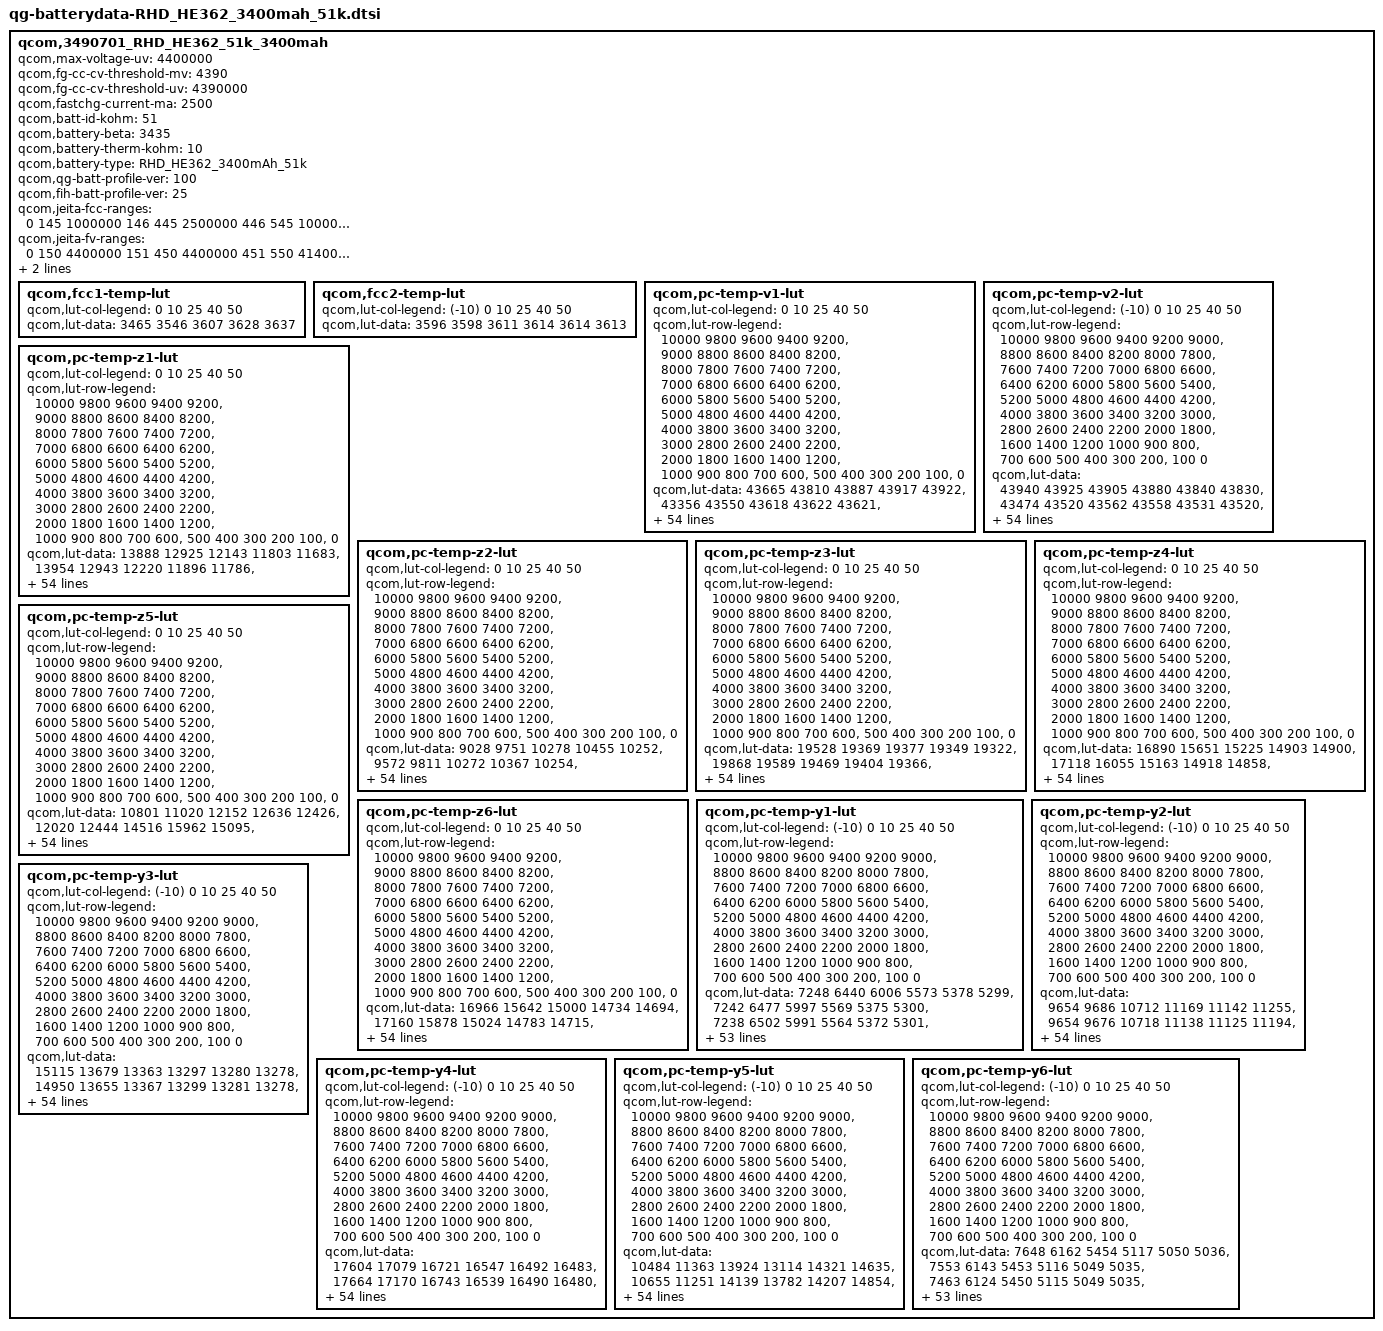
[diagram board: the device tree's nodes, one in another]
qcom,3490701_RHD_HE362_51k_3400mah {
	/* 3490701_FIH_HE362_3500mAh_averaged_MasterSlave_Jul26th2018 */
	qcom,max-voltage-uv = <4400000>;
	qcom,fg-cc-cv-threshold-mv = <4390>;
	qcom,fg-cc-cv-threshold-uv = <4390000>; // not use
	qcom,fastchg-current-ma = <2500>;
	qcom,batt-id-kohm = <51>;
	qcom,battery-beta = <3435>;
	qcom,battery-therm-kohm = <10>;
	qcom,battery-type =
		"RHD_HE362_3400mAh_51k";
	qcom,qg-batt-profile-ver = <100>;
	qcom,fih-batt-profile-ver = <25>;

	qcom,jeita-fcc-ranges = <0   145   1000000
				 146 445  2500000
				 446 545  1000000
				 546 550  100000>;
	qcom,jeita-fv-ranges =  <0   150  4400000
				 151 450  4400000
				 451 550  4140000>;

	qcom,jeita-soft-thresholds = <0x257d 0xfb3>; 
	qcom,jeita-hard-thresholds = <0x3733 0xbc2>;

	qcom,fcc1-temp-lut {
		qcom,lut-col-legend = <0 10 25 40 50>;
		qcom,lut-data = <3465 3546 3607 3628 3637>;
	};

	qcom,fcc2-temp-lut {
		qcom,lut-col-legend = <(-10) 0 10 25 40 50>;
		qcom,lut-data = <3596 3598 3611 3614 3614 3613>;
	};

	qcom,pc-temp-v1-lut {
		qcom,lut-col-legend = <0 10 25 40 50>;
		qcom,lut-row-legend = <10000 9800 9600 9400 9200>,
			<9000 8800 8600 8400 8200>,
			<8000 7800 7600 7400 7200>,
			<7000 6800 6600 6400 6200>,
			<6000 5800 5600 5400 5200>,
			<5000 4800 4600 4400 4200>,
			<4000 3800 3600 3400 3200>,
			<3000 2800 2600 2400 2200>,
			<2000 1800 1600 1400 1200>,
			<1000 900 800 700 600>,
			<500 400 300 200 100>,
			<0>;
		qcom,lut-data = <43665 43810 43887 43917 43922>,
			<43356 43550 43618 43622 43621>,
			<43072 43273 43356 43371 43365>,
			<42816 43000 43101 43124 43119>,
			<42577 42745 42851 42876 42877>,
			<42342 42500 42603 42631 42635>,
			<42113 42262 42358 42389 42395>,
			<41890 42030 42118 42149 42157>,
			<41671 41804 41880 41911 41923>,
			<41457 41583 41649 41676 41691>,
			<41257 41368 41419 41447 41461>,
			<41079 41171 41202 41223 41233>,
			<40888 40999 41009 41004 41012>,
			<40629 40807 40830 40791 40798>,
			<40330 40535 40621 40585 40590>,
			<40101 40242 40358 40384 40390>,
			<39935 40044 40122 40191 40198>,
			<39792 39906 39961 40012 40015>,
			<39654 39776 39825 39842 39840>,
			<39526 39645 39681 39679 39673>,
			<39403 39514 39537 39530 39523>,
			<39284 39369 39364 39365 39361>,
			<39168 39214 39096 39134 39143>,
			<39056 39042 38824 38879 38897>,
			<38949 38817 38681 38711 38718>,
			<38844 38607 38589 38597 38589>,
			<38741 38502 38506 38496 38478>,
			<38643 38435 38425 38393 38377>,
			<38550 38383 38350 38298 38287>,
			<38461 38343 38278 38217 38203>,
			<38393 38307 38212 38146 38128>,
			<38340 38269 38155 38083 38060>,
			<38297 38231 38107 38030 38003>,
			<38260 38195 38065 37981 37950>,
			<38230 38165 38028 37941 37904>,
			<38205 38133 37994 37904 37862>,
			<38189 38100 37958 37862 37814>,
			<38173 38065 37922 37818 37760>,
			<38139 38015 37875 37763 37695>,
			<38070 37931 37797 37687 37615>,
			<37982 37828 37696 37591 37520>,
			<37863 37715 37586 37483 37412>,
			<37720 37583 37459 37357 37286>,
			<37558 37419 37306 37205 37135>,
			<37392 37262 37155 37057 36991>,
			<37264 37172 37054 36960 36901>,
			<37223 37148 37026 36936 36875>,
			<37190 37121 37008 36919 36857>,
			<37155 37096 36991 36900 36839>,
			<37106 37055 36954 36855 36784>,
			<36934 36856 36755 36620 36520>,
			<36474 36402 36320 36171 36058>,
			<35825 35759 35692 35542 35435>,
			<34864 34757 34770 34653 34545>,
			<33230 33191 33337 33243 33145>,
			<30000 30000 30000 30000 30000>;
	};

	qcom,pc-temp-v2-lut {
		qcom,lut-col-legend = <(-10) 0 10 25 40 50>;
		qcom,lut-row-legend = <10000 9800 9600 9400 9200 9000>,
			<8800 8600 8400 8200 8000 7800>,
			<7600 7400 7200 7000 6800 6600>,
			<6400 6200 6000 5800 5600 5400>,
			<5200 5000 4800 4600 4400 4200>,
			<4000 3800 3600 3400 3200 3000>,
			<2800 2600 2400 2200 2000 1800>,
			<1600 1400 1200 1000 900 800>,
			<700 600 500 400 300 200>,
			<100 0>;
		qcom,lut-data = <43940 43925 43905 43880 43840 43830>,
			<43474 43520 43562 43558 43531 43520>,
			<43059 43153 43247 43259 43241 43230>,
			<42701 42828 42960 42986 42973 42962>,
			<42389 42539 42700 42736 42725 42715>,
			<42103 42273 42449 42492 42481 42473>,
			<41832 42030 42199 42248 42238 42231>,
			<41586 41798 41957 42009 42000 41993>,
			<41377 41548 41722 41774 41765 41758>,
			<41191 41291 41494 41543 41533 41526>,
			<41027 41088 41273 41316 41307 41298>,
			<40898 40951 41064 41094 41085 41075>,
			<40740 40802 40854 40877 40868 40857>,
			<40393 40534 40637 40671 40658 40648>,
			<39897 40183 40415 40470 40452 40444>,
			<39584 39924 40193 40263 40254 40248>,
			<39402 39742 39967 40047 40062 40057>,
			<39234 39561 39762 39853 39880 39875>,
			<39043 39347 39592 39698 39712 39706>,
			<38855 39124 39429 39550 39547 39541>,
			<38686 38921 39232 39362 39371 39366>,
			<38529 38729 39003 39138 39185 39185>,
			<38398 38560 38803 38928 38990 38992>,
			<38292 38409 38640 38731 38768 38770>,
			<38202 38280 38496 38558 38566 38566>,
			<38121 38179 38362 38427 38430 38429>,
			<38050 38097 38238 38320 38324 38323>,
			<37983 38029 38137 38222 38227 38224>,
			<37920 37970 38052 38132 38138 38132>,
			<37860 37919 37981 38051 38057 38048>,
			<37806 37873 37920 37977 37984 37975>,
			<37756 37833 37869 37909 37917 37907>,
			<37708 37797 37832 37851 37858 37848>,
			<37662 37764 37806 37801 37806 37796>,
			<37615 37734 37779 37755 37750 37736>,
			<37567 37703 37747 37715 37682 37650>,
			<37517 37672 37711 37674 37609 37554>,
			<37462 37634 37667 37621 37532 37466>,
			<37404 37587 37612 37552 37451 37382>,
			<37327 37526 37545 37479 37374 37303>,
			<37199 37437 37459 37401 37305 37232>,
			<37029 37324 37351 37305 37219 37146>,
			<36804 37180 37217 37183 37099 37027>,
			<36635 36995 37056 37054 36972 36902>,
			<36547 36753 36862 36898 36821 36762>,
			<36429 36619 36758 36838 36785 36729>,
			<36366 36572 36717 36818 36769 36714>,
			<36300 36513 36674 36793 36747 36695>,
			<36224 36436 36623 36754 36713 36660>,
			<36112 36321 36528 36671 36626 36557>,
			<35886 36087 36289 36421 36338 36226>,
			<35442 35550 35776 35919 35823 35699>,
			<34781 34748 35048 35228 35129 34986>,
			<33819 33748 33939 34269 34156 33982>,
			<32276 32311 32325 32813 32666 32410>,
			<28288 28796 27593 28640 28095 27772>;
	};

	qcom,pc-temp-z1-lut {
		qcom,lut-col-legend = <0 10 25 40 50>;
		qcom,lut-row-legend = <10000 9800 9600 9400 9200>,
			<9000 8800 8600 8400 8200>,
			<8000 7800 7600 7400 7200>,
			<7000 6800 6600 6400 6200>,
			<6000 5800 5600 5400 5200>,
			<5000 4800 4600 4400 4200>,
			<4000 3800 3600 3400 3200>,
			<3000 2800 2600 2400 2200>,
			<2000 1800 1600 1400 1200>,
			<1000 900 800 700 600>,
			<500 400 300 200 100>,
			<0>;
		qcom,lut-data = <13888 12925 12143 11803 11683>,
			<13954 12943 12220 11896 11786>,
			<13996 12967 12228 11897 11787>,
			<14013 12982 12223 11892 11784>,
			<14025 12987 12219 11888 11782>,
			<14034 12990 12215 11884 11780>,
			<14043 12992 12213 11879 11778>,
			<14049 12993 12210 11876 11775>,
			<14060 12997 12203 11874 11773>,
			<14078 13006 12199 11872 11771>,
			<14082 13018 12199 11870 11770>,
			<14070 13019 12199 11869 11770>,
			<14054 13011 12198 11869 11771>,
			<14037 13001 12196 11869 11771>,
			<14015 12988 12194 11869 11772>,
			<14009 12974 12188 11870 11774>,
			<14031 12973 12184 11872 11776>,
			<14051 12982 12185 11872 11778>,
			<14043 12987 12189 11873 11780>,
			<14022 12990 12193 11874 11781>,
			<14013 12994 12200 11877 11783>,
			<14008 12997 12204 11881 11785>,
			<14002 13006 12205 11883 11788>,
			<14012 13015 12206 11886 11792>,
			<14044 13022 12209 11889 11795>,
			<14069 13029 12216 11894 11799>,
			<14085 13034 12221 11898 11803>,
			<14098 13042 12224 11903 11807>,
			<14110 13046 12227 11907 11810>,
			<14123 13060 12232 11910 11814>,
			<14127 13074 12238 11914 11817>,
			<14115 13066 12242 11917 11820>,
			<14102 13045 12243 11919 11823>,
			<14104 13037 12244 11922 11825>,
			<14118 13042 12249 11925 11828>,
			<14130 13050 12253 11930 11831>,
			<14136 13062 12254 11932 11834>,
			<14139 13080 12252 11933 11836>,
			<14136 13090 12251 11934 11839>,
			<14128 13096 12258 11938 11841>,
			<14124 13099 12265 11944 11843>,
			<14144 13095 12268 11948 11846>,
			<14160 13091 12269 11952 11849>,
			<14130 13101 12269 11952 11851>,
			<14080 13109 12270 11952 11853>,
			<14077 13082 12283 11957 11855>,
			<14092 13090 12275 11957 11855>,
			<14140 13078 12274 11957 11857>,
			<14045 13079 12274 11958 11859>,
			<14052 13095 12279 11966 11864>,
			<14061 13110 12292 11972 11871>,
			<14074 13138 12305 11983 11879>,
			<14089 13146 12319 12000 11894>,
			<14144 13173 12345 12024 11916>,
			<14144 13173 12345 12024 11916>,
			<14144 13173 12345 12024 11916>;
	};

	qcom,pc-temp-z2-lut {
		qcom,lut-col-legend = <0 10 25 40 50>;
		qcom,lut-row-legend = <10000 9800 9600 9400 9200>,
			<9000 8800 8600 8400 8200>,
			<8000 7800 7600 7400 7200>,
			<7000 6800 6600 6400 6200>,
			<6000 5800 5600 5400 5200>,
			<5000 4800 4600 4400 4200>,
			<4000 3800 3600 3400 3200>,
			<3000 2800 2600 2400 2200>,
			<2000 1800 1600 1400 1200>,
			<1000 900 800 700 600>,
			<500 400 300 200 100>,
			<0>;
		qcom,lut-data = <9028 9751 10278 10455 10252>,
			<9572 9811 10272 10367 10254>,
			<9873 9926 10272 10391 10397>,
			<9933 10024 10247 10375 10397>,
			<9966 10012 10216 10351 10391>,
			<9973 9976 10187 10329 10384>,
			<9969 9948 10163 10308 10363>,
			<9963 9925 10166 10305 10334>,
			<9955 9912 10184 10333 10284>,
			<9944 9909 10198 10354 10248>,
			<9931 9908 10208 10351 10254>,
			<9917 9913 10219 10346 10269>,
			<9899 9948 10235 10343 10273>,
			<9859 9972 10253 10348 10262>,
			<9804 9971 10257 10347 10260>,
			<9791 9968 10250 10324 10277>,
			<9822 9973 10246 10298 10295>,
			<9853 10005 10256 10294 10302>,
			<9853 10037 10277 10294 10306>,
			<9844 10061 10293 10300 10311>,
			<9837 10080 10309 10329 10321>,
			<9828 10090 10315 10359 10336>,
			<9821 10098 10298 10362 10354>,
			<9822 10102 10271 10346 10379>,
			<9829 10089 10255 10348 10424>,
			<9837 10073 10243 10409 10522>,
			<9850 10076 10242 10447 10576>,
			<9866 10093 10281 10412 10468>,
			<9880 10105 10319 10357 10314>,
			<9895 10111 10305 10325 10278>,
			<9909 10116 10272 10295 10265>,
			<9923 10120 10263 10287 10262>,
			<9936 10123 10266 10302 10268>,
			<9952 10128 10270 10326 10274>,
			<9971 10139 10289 10357 10279>,
			<9974 10152 10319 10396 10290>,
			<9785 10164 10340 10426 10307>,
			<9531 10178 10355 10449 10351>,
			<9446 10193 10372 10470 10390>,
			<9395 10213 10398 10495 10417>,
			<9375 10229 10420 10516 10442>,
			<9376 10233 10423 10517 10437>,
			<9379 10236 10420 10510 10413>,
			<9407 10253 10430 10480 10399>,
			<9439 10346 10462 10461 10394>,
			<9437 10293 10529 10503 10417>,
			<9421 10048 10510 10470 10414>,
			<9451 9984 10513 10481 10397>,
			<9447 10104 10540 10477 10469>,
			<9428 10119 10548 10573 10607>,
			<9400 9990 10685 10470 10307>,
			<9321 9877 10657 10324 10172>,
			<9256 9640 10375 10252 10116>,
			<9166 10084 10236 10123 10043>,
			<9166 10084 10236 10123 10043>,
			<9166 10084 10236 10123 10043>;
	};

	qcom,pc-temp-z3-lut {
		qcom,lut-col-legend = <0 10 25 40 50>;
		qcom,lut-row-legend = <10000 9800 9600 9400 9200>,
			<9000 8800 8600 8400 8200>,
			<8000 7800 7600 7400 7200>,
			<7000 6800 6600 6400 6200>,
			<6000 5800 5600 5400 5200>,
			<5000 4800 4600 4400 4200>,
			<4000 3800 3600 3400 3200>,
			<3000 2800 2600 2400 2200>,
			<2000 1800 1600 1400 1200>,
			<1000 900 800 700 600>,
			<500 400 300 200 100>,
			<0>;
		qcom,lut-data = <19528 19369 19377 19349 19322>,
			<19868 19589 19469 19404 19366>,
			<20033 19713 19531 19431 19403>,
			<20017 19785 19544 19443 19418>,
			<19977 19806 19549 19449 19423>,
			<19939 19818 19550 19450 19423>,
			<19894 19820 19550 19449 19418>,
			<19866 19814 19548 19447 19412>,
			<19869 19806 19539 19440 19400>,
			<19878 19798 19530 19433 19390>,
			<19884 19787 19522 19424 19387>,
			<19885 19767 19512 19416 19386>,
			<19889 19722 19500 19411 19384>,
			<19937 19694 19487 19409 19379>,
			<20032 19710 19484 19405 19375>,
			<20066 19736 19493 19399 19370>,
			<20051 19734 19500 19391 19366>,
			<20031 19697 19493 19386 19364>,
			<20005 19670 19481 19382 19362>,
			<19954 19661 19474 19381 19360>,
			<19937 19655 19469 19381 19357>,
			<19958 19659 19467 19382 19355>,
			<19981 19678 19482 19385 19355>,
			<19987 19692 19500 19389 19357>,
			<19991 19700 19495 19388 19366>,
			<19992 19705 19472 19382 19406>,
			<19988 19705 19464 19379 19431>,
			<19983 19703 19477 19410 19426>,
			<19977 19700 19495 19447 19418>,
			<19970 19694 19508 19448 19412>,
			<19961 19687 19520 19443 19406>,
			<19946 19682 19522 19436 19400>,
			<19925 19679 19513 19429 19394>,
			<19907 19675 19503 19421 19388>,
			<19887 19668 19497 19414 19380>,
			<19851 19660 19491 19406 19372>,
			<19660 19654 19485 19401 19368>,
			<19429 19649 19481 19396 19365>,
			<19347 19643 19476 19393 19364>,
			<19297 19638 19472 19391 19365>,
			<19277 19633 19467 19388 19367>,
			<19277 19625 19464 19385 19365>,
			<19277 19616 19461 19380 19361>,
			<19275 19607 19454 19375 19360>,
			<19272 19576 19443 19372 19359>,
			<19272 19401 19427 19371 19347>,
			<19273 19273 19427 19360 19342>,
			<19271 19265 19418 19352 19340>,
			<19271 19264 19397 19352 19330>,
			<19272 19264 19396 19342 19319>,
			<19273 19265 19359 19356 19359>,
			<19278 19266 19348 19372 19375>,
			<19284 19274 19432 19401 19372>,
			<19312 19611 19477 19402 19390>,
			<19312 19611 19477 19402 19390>,
			<19312 19611 19477 19402 19390>;
	};

	qcom,pc-temp-z4-lut {
		qcom,lut-col-legend = <0 10 25 40 50>;
		qcom,lut-row-legend = <10000 9800 9600 9400 9200>,
			<9000 8800 8600 8400 8200>,
			<8000 7800 7600 7400 7200>,
			<7000 6800 6600 6400 6200>,
			<6000 5800 5600 5400 5200>,
			<5000 4800 4600 4400 4200>,
			<4000 3800 3600 3400 3200>,
			<3000 2800 2600 2400 2200>,
			<2000 1800 1600 1400 1200>,
			<1000 900 800 700 600>,
			<500 400 300 200 100>,
			<0>;
		qcom,lut-data = <16890 15651 15225 14903 14900>,
			<17118 16055 15163 14918 14858>,
			<17180 15881 15267 15001 14919>,
			<16994 15651 15145 14960 14895>,
			<16608 15471 15030 14901 14852>,
			<16343 15303 14966 14860 14820>,
			<16161 15184 14915 14827 14793>,
			<16005 15098 14871 14806 14783>,
			<15864 15032 14833 14792 14781>,
			<15739 14981 14812 14782 14779>,
			<15626 14940 14805 14774 14772>,
			<15522 14908 14798 14768 14761>,
			<15431 14878 14783 14760 14752>,
			<15356 14860 14764 14749 14745>,
			<15288 14855 14759 14740 14738>,
			<15226 14851 14761 14736 14731>,
			<15158 14843 14763 14733 14724>,
			<15110 14830 14749 14727 14716>,
			<15096 14816 14724 14719 14707>,
			<15083 14801 14719 14712 14702>,
			<15056 14788 14719 14706 14700>,
			<14996 14784 14722 14704 14698>,
			<14937 14784 14812 14765 14747>,
			<14905 14789 14927 14874 14847>,
			<14882 14880 14941 14895 14864>,
			<14873 14988 14938 14886 14811>,
			<14870 14994 14929 14871 14766>,
			<14869 14971 14891 14821 14751>,
			<14872 14945 14844 14762 14741>,
			<14880 14913 14811 14744 14732>,
			<14883 14881 14783 14735 14723>,
			<14879 14857 14769 14729 14717>,
			<14871 14836 14762 14723 14710>,
			<14864 14818 14757 14719 14707>,
			<14856 14804 14753 14719 14707>,
			<14856 14792 14749 14719 14709>,
			<15038 14782 14748 14720 14712>,
			<15275 14774 14747 14723 14719>,
			<15337 14773 14747 14728 14723>,
			<15357 14777 14753 14732 14722>,
			<15358 14781 14761 14736 14720>,
			<15346 14775 14756 14734 14716>,
			<15327 14764 14743 14725 14709>,
			<15296 14758 14741 14729 14712>,
			<15187 14743 14733 14730 14714>,
			<15124 14853 14703 14699 14697>,
			<15119 14985 14692 14697 14689>,
			<15111 14986 14685 14685 14669>,
			<15104 14976 14690 14662 14657>,
			<15100 14971 14688 14672 14667>,
			<15101 14986 14753 14689 14661>,
			<15147 15012 14780 14685 14663>,
			<15194 15034 14703 14678 14683>,
			<15290 14768 14730 14719 14698>,
			<15290 14768 14730 14719 14698>,
			<15290 14768 14730 14719 14698>;
	};

	qcom,pc-temp-z5-lut {
		qcom,lut-col-legend = <0 10 25 40 50>;
		qcom,lut-row-legend = <10000 9800 9600 9400 9200>,
			<9000 8800 8600 8400 8200>,
			<8000 7800 7600 7400 7200>,
			<7000 6800 6600 6400 6200>,
			<6000 5800 5600 5400 5200>,
			<5000 4800 4600 4400 4200>,
			<4000 3800 3600 3400 3200>,
			<3000 2800 2600 2400 2200>,
			<2000 1800 1600 1400 1200>,
			<1000 900 800 700 600>,
			<500 400 300 200 100>,
			<0>;
		qcom,lut-data = <10801 11020 12152 12636 12426>,
			<12020 12444 14516 15962 15095>,
			<12675 13477 15198 15871 16573>,
			<12755 14333 15608 16200 17288>,
			<12797 14998 16012 16700 17700>,
			<12831 15546 16427 17157 18074>,
			<12862 16006 16882 17592 18389>,
			<12906 16386 17566 17877 18404>,
			<13031 16751 18490 18174 17617>,
			<13211 17232 18839 18351 16947>,
			<13277 17686 18768 18188 17110>,
			<13241 17682 18672 17909 17513>,
			<13218 17106 18584 17977 17775>,
			<13698 16715 18498 18553 17914>,
			<14799 18602 18623 18870 17929>,
			<15506 21585 19913 18639 17969>,
			<15824 21780 21301 18343 18143>,
			<15939 20006 22102 18476 18639>,
			<15636 18929 22758 19037 19616>,
			<14953 19394 23083 19756 20279>,
			<14869 20457 23302 20951 20734>,
			<16048 22991 23745 21731 21000>,
			<17812 29532 27933 21529 20115>,
			<19593 33932 32941 20890 18194>,
			<21704 35716 30748 19551 17802>,
			<23946 36778 22145 16363 18682>,
			<26499 36036 18641 14803 19575>,
			<28941 32976 18913 17221 19997>,
			<31000 30482 19485 20934 20403>,
			<32947 28698 21503 23010 21127>,
			<33588 27554 25340 24502 22289>,
			<32513 27679 27409 25887 23471>,
			<30727 28305 28397 27519 24853>,
			<29064 28814 29151 28523 25758>,
			<27050 29361 29999 28516 25698>,
			<24258 29905 30729 28376 25401>,
			<18080 30509 30718 27952 24924>,
			<12096 31359 29993 26325 23850>,
			<11125 31723 28998 24552 22781>,
			<10942 31837 27336 22901 22091>,
			<10889 31872 25633 21280 21445>,
			<10911 30632 24954 20214 20535>,
			<10941 28745 24529 19407 19419>,
			<10966 28593 22900 18138 18699>,
			<11139 27423 22355 17692 17995>,
			<11232 17507 22845 19055 16978>,
			<11218 11650 22927 17455 16640>,
			<11170 11285 21557 17178 17495>,
			<11157 11230 18148 18852 17309>,
			<11156 11231 18310 16890 15458>,
			<11181 11292 14268 16165 19645>,
			<11156 11211 13142 17231 22018>,
			<11052 11165 20058 22840 18779>,
			<11085 27605 25375 18676 18980>,
			<11085 27605 25375 18676 18980>,
			<11085 27605 25375 18676 18980>;
	};

	qcom,pc-temp-z6-lut {
		qcom,lut-col-legend = <0 10 25 40 50>;
		qcom,lut-row-legend = <10000 9800 9600 9400 9200>,
			<9000 8800 8600 8400 8200>,
			<8000 7800 7600 7400 7200>,
			<7000 6800 6600 6400 6200>,
			<6000 5800 5600 5400 5200>,
			<5000 4800 4600 4400 4200>,
			<4000 3800 3600 3400 3200>,
			<3000 2800 2600 2400 2200>,
			<2000 1800 1600 1400 1200>,
			<1000 900 800 700 600>,
			<500 400 300 200 100>,
			<0>;
		qcom,lut-data = <16966 15642 15000 14734 14694>,
			<17160 15878 15024 14783 14715>,
			<17221 15826 15092 14833 14761>,
			<17095 15749 15041 14818 14755>,
			<16833 15666 14991 14797 14743>,
			<16646 15571 14961 14781 14730>,
			<16510 15500 14935 14765 14717>,
			<16401 15445 14910 14752 14706>,
			<16319 15400 14887 14742 14699>,
			<16251 15364 14872 14734 14693>,
			<16189 15334 14863 14725 14687>,
			<16121 15299 14855 14718 14682>,
			<16079 15255 14841 14711 14676>,
			<16071 15232 14825 14705 14671>,
			<16068 15235 14820 14699 14665>,
			<16059 15239 14824 14694 14660>,
			<16024 15236 14827 14688 14655>,
			<15980 15212 14818 14683 14650>,
			<15943 15193 14802 14678 14646>,
			<15908 15183 14798 14675 14642>,
			<15888 15177 14797 14673 14640>,
			<15875 15178 14797 14672 14639>,
			<15868 15189 14844 14700 14661>,
			<15865 15206 14904 14750 14706>,
			<15863 15254 14909 14760 14717>,
			<15863 15302 14900 14754 14716>,
			<15863 15305 14890 14748 14713>,
			<15863 15296 14882 14743 14707>,
			<15864 15286 14874 14738 14698>,
			<15865 15272 14869 14733 14691>,
			<15865 15257 14864 14726 14685>,
			<15859 15246 14859 14720 14679>,
			<15848 15237 14852 14714 14673>,
			<15838 15228 14846 14709 14668>,
			<15825 15220 14841 14704 14664>,
			<15812 15214 14838 14700 14660>,
			<15797 15211 14835 14699 14660>,
			<15783 15208 14832 14698 14661>,
			<15774 15208 14832 14698 14662>,
			<15767 15212 14834 14699 14663>,
			<15761 15215 14836 14700 14663>,
			<15758 15214 14834 14698 14661>,
			<15754 15210 14829 14693 14656>,
			<15743 15208 14826 14693 14658>,
			<15697 15195 14819 14692 14658>,
			<15672 15161 14801 14679 14645>,
			<15672 15154 14797 14673 14640>,
			<15668 15153 14790 14664 14630>,
			<15667 15150 14782 14654 14619>,
			<15672 15154 14783 14655 14619>,
			<15685 15169 14796 14671 14639>,
			<15721 15194 14808 14681 14651>,
			<15765 15225 14830 14697 14662>,
			<15850 15311 14879 14725 14685>,
			<15850 15311 14879 14725 14685>,
			<15850 15311 14879 14725 14685>;
	};

	qcom,pc-temp-y1-lut {
		qcom,lut-col-legend = <(-10) 0 10 25 40 50>;
		qcom,lut-row-legend = <10000 9800 9600 9400 9200 9000>,
			<8800 8600 8400 8200 8000 7800>,
			<7600 7400 7200 7000 6800 6600>,
			<6400 6200 6000 5800 5600 5400>,
			<5200 5000 4800 4600 4400 4200>,
			<4000 3800 3600 3400 3200 3000>,
			<2800 2600 2400 2200 2000 1800>,
			<1600 1400 1200 1000 900 800>,
			<700 600 500 400 300 200>,
			<100 0>;
		qcom,lut-data = <7248 6440 6006 5573 5378 5299>,
			<7242 6477 5997 5569 5375 5300>,
			<7238 6502 5991 5564 5372 5301>,
			<7236 6516 5988 5560 5369 5301>,
			<7235 6522 5986 5556 5367 5300>,
			<7234 6523 5985 5555 5364 5300>,
			<7249 6509 5988 5556 5362 5297>,
			<7266 6494 5990 5558 5361 5294>,
			<7263 6494 5989 5555 5359 5292>,
			<7252 6500 5985 5547 5358 5290>,
			<7248 6502 5983 5544 5356 5289>,
			<7253 6500 5983 5544 5355 5288>,
			<7259 6499 5982 5544 5353 5287>,
			<7262 6499 5983 5546 5351 5287>,
			<7265 6501 5984 5550 5349 5287>,
			<7263 6505 5985 5550 5349 5287>,
			<7249 6519 5981 5546 5350 5288>,
			<7239 6528 5979 5543 5351 5289>,
			<7242 6522 5976 5543 5350 5289>,
			<7248 6513 5972 5544 5350 5290>,
			<7254 6511 5972 5545 5351 5290>,
			<7264 6511 5975 5546 5352 5290>,
			<7268 6511 5979 5546 5353 5290>,
			<7271 6513 5989 5547 5355 5291>,
			<7274 6515 5997 5548 5357 5293>,
			<7272 6520 5994 5549 5358 5294>,
			<7266 6529 5986 5551 5359 5296>,
			<7263 6532 5985 5554 5360 5297>,
			<7261 6520 5986 5555 5361 5299>,
			<7260 6510 5987 5557 5362 5302>,
			<7254 6519 5989 5559 5365 5304>,
			<7240 6539 5990 5561 5369 5307>,
			<7237 6542 5988 5563 5372 5310>,
			<7246 6524 5984 5566 5376 5311>,
			<7255 6513 5984 5567 5380 5313>,
			<7251 6518 5986 5567 5383 5316>,
			<7243 6526 5988 5568 5384 5319>,
			<7250 6531 5989 5571 5385 5321>,
			<7284 6539 5988 5575 5386 5323>,
			<7302 6541 5988 5578 5387 5324>,
			<7287 6542 5989 5579 5390 5326>,
			<7271 6544 5991 5581 5391 5327>,
			<7266 6559 5993 5586 5391 5328>,
			<7264 6552 6002 5588 5395 5330>,
			<7330 6555 6027 5581 5398 5333>,
			<7284 6564 6007 5585 5402 5337>,
			<7285 6558 6023 5587 5402 5338>,
			<7322 6562 6032 5589 5405 5338>,
			<7295 6582 6014 5593 5406 5337>,
			<7284 6586 6019 5602 5407 5339>,
			<7303 6580 6031 5606 5412 5343>,
			<7361 6593 6034 5614 5421 5351>,
			<7349 6612 6066 5634 5441 5367>,
			<7461 6638 6083 5654 5468 5392>,
			<7461 6638 6083 5654 5468 5392>,
			<7461 6638 6083 5654 5468 5392>;
	};

	qcom,pc-temp-y2-lut {
		qcom,lut-col-legend = <(-10) 0 10 25 40 50>;
		qcom,lut-row-legend = <10000 9800 9600 9400 9200 9000>,
			<8800 8600 8400 8200 8000 7800>,
			<7600 7400 7200 7000 6800 6600>,
			<6400 6200 6000 5800 5600 5400>,
			<5200 5000 4800 4600 4400 4200>,
			<4000 3800 3600 3400 3200 3000>,
			<2800 2600 2400 2200 2000 1800>,
			<1600 1400 1200 1000 900 800>,
			<700 600 500 400 300 200>,
			<100 0>;
		qcom,lut-data = <9654 9686 10712 11169 11142 11255>,
			<9654 9676 10718 11138 11125 11194>,
			<9654 9672 10717 11106 11099 11134>,
			<9655 9673 10710 11075 11073 11078>,
			<9655 9677 10699 11048 11051 11031>,
			<9656 9686 10686 11029 11041 10996>,
			<9656 9800 10666 11016 11038 10969>,
			<9656 9935 10645 11004 11035 10949>,
			<9656 9966 10630 10987 11026 10937>,
			<9656 9997 10618 10959 11008 10929>,
			<9657 10051 10606 10936 10987 10926>,
			<9657 10262 10591 10910 10938 10938>,
			<9657 10438 10583 10888 10900 10948>,
			<9657 10349 10615 10873 10900 10929>,
			<9657 10145 10684 10861 10904 10896>,
			<9657 10092 10723 10863 10897 10890>,
			<9657 10114 10745 10884 10877 10901>,
			<9657 10128 10761 10914 10865 10914>,
			<9657 9980 10774 10961 10901 10919>,
			<9657 9755 10784 11006 10971 10926>,
			<9657 9706 10794 11004 11056 10977>,
			<9657 9693 10805 10981 11167 11099>,
			<9657 9687 10817 10975 11206 11148>,
			<9657 9684 10843 11031 11160 11105>,
			<9657 9682 10867 11089 11114 11063>,
			<9657 9680 10706 11095 11122 11071>,
			<9657 9679 10301 11095 11150 11098>,
			<9657 9678 10208 11100 11162 11128>,
			<9657 9676 10583 11124 11167 11171>,
			<9656 9674 10885 11142 11164 11199>,
			<9656 9672 10745 11142 11158 11192>,
			<9656 9670 10450 11140 11154 11178>,
			<9656 9669 10407 11139 11163 11180>,
			<9656 9669 10647 11135 11210 11202>,
			<9656 9668 10806 11129 11237 11216>,
			<9656 9666 10785 11114 11181 11195>,
			<9655 9665 10754 11095 11117 11160>,
			<9655 9663 10722 11084 11115 11135>,
			<9655 9662 10685 11075 11127 11113>,
			<9655 9661 10646 11063 11135 11104>,
			<9655 9660 10608 11038 11138 11104>,
			<9654 9658 10565 11024 11133 11085>,
			<9654 9658 10515 11017 11102 11036>,
			<9654 9657 10220 10977 11103 11046>,
			<9654 9656 9784 10951 11127 11025>,
			<9654 9655 9724 10870 10981 10966>,
			<9654 9655 9714 10873 11017 10909>,
			<9653 9655 9700 10848 10982 10881>,
			<9653 9655 9690 10828 10941 10851>,
			<9653 9654 9679 10764 10913 10863>,
			<9653 9654 9674 10707 10878 10793>,
			<9652 9654 9668 10618 10827 10680>,
			<9651 9653 9665 10546 10728 10647>,
			<9650 9653 9661 10520 10635 10571>,
			<9650 9653 9661 10520 10635 10571>,
			<9650 9653 9661 10520 10635 10571>;
	};

	qcom,pc-temp-y3-lut {
		qcom,lut-col-legend = <(-10) 0 10 25 40 50>;
		qcom,lut-row-legend = <10000 9800 9600 9400 9200 9000>,
			<8800 8600 8400 8200 8000 7800>,
			<7600 7400 7200 7000 6800 6600>,
			<6400 6200 6000 5800 5600 5400>,
			<5200 5000 4800 4600 4400 4200>,
			<4000 3800 3600 3400 3200 3000>,
			<2800 2600 2400 2200 2000 1800>,
			<1600 1400 1200 1000 900 800>,
			<700 600 500 400 300 200>,
			<100 0>;
		qcom,lut-data = <15115 13679 13363 13297 13280 13278>,
			<14950 13655 13367 13299 13281 13278>,
			<14792 13632 13371 13300 13281 13278>,
			<14645 13610 13375 13302 13282 13279>,
			<14518 13591 13378 13303 13282 13279>,
			<14415 13575 13381 13303 13282 13280>,
			<14340 13562 13383 13303 13283 13281>,
			<14271 13551 13385 13302 13283 13281>,
			<14170 13543 13387 13302 13283 13281>,
			<14049 13538 13389 13302 13283 13281>,
			<14012 13529 13391 13303 13283 13280>,
			<14039 13498 13396 13310 13287 13281>,
			<14063 13473 13400 13316 13291 13281>,
			<14020 13479 13399 13317 13291 13283>,
			<13926 13493 13396 13316 13292 13287>,
			<13897 13496 13392 13317 13292 13288>,
			<13894 13492 13385 13319 13291 13287>,
			<13893 13486 13380 13320 13290 13287>,
			<13892 13481 13377 13321 13293 13288>,
			<13892 13473 13374 13321 13297 13291>,
			<13892 13462 13369 13320 13299 13292>,
			<13889 13445 13361 13316 13300 13293>,
			<13888 13435 13355 13311 13299 13293>,
			<13896 13431 13352 13305 13292 13286>,
			<13910 13429 13350 13301 13284 13279>,
			<13927 13431 13336 13301 13283 13279>,
			<13950 13439 13311 13301 13283 13279>,
			<13975 13448 13305 13300 13283 13279>,
			<14003 13459 13323 13300 13284 13279>,
			<14037 13472 13337 13299 13286 13279>,
			<14079 13489 13334 13300 13285 13279>,
			<14131 13513 13328 13300 13285 13280>,
			<14185 13539 13329 13301 13285 13280>,
			<14240 13569 13344 13304 13286 13280>,
			<14298 13601 13356 13305 13287 13280>,
			<14358 13634 13361 13306 13287 13279>,
			<14422 13669 13364 13306 13287 13278>,
			<14488 13706 13368 13306 13286 13278>,
			<14557 13745 13372 13307 13282 13279>,
			<14628 13790 13377 13306 13281 13279>,
			<14706 13846 13383 13305 13285 13280>,
			<14772 13909 13389 13305 13288 13281>,
			<14815 13978 13394 13307 13288 13280>,
			<14868 14061 13397 13310 13288 13284>,
			<14842 14067 13388 13308 13282 13279>,
			<15034 14213 13423 13311 13291 13283>,
			<15136 14299 13441 13316 13293 13286>,
			<15257 14388 13468 13321 13295 13290>,
			<15411 14485 13504 13329 13302 13295>,
			<15589 14600 13549 13336 13306 13296>,
			<15805 14718 13588 13341 13304 13293>,
			<16074 14827 13631 13348 13306 13295>,
			<16778 14976 13702 13360 13312 13299>,
			<18452 15250 13772 13374 13324 13309>,
			<18452 15250 13772 13374 13324 13309>,
			<18452 15250 13772 13374 13324 13309>;
	};

	qcom,pc-temp-y4-lut {
		qcom,lut-col-legend = <(-10) 0 10 25 40 50>;
		qcom,lut-row-legend = <10000 9800 9600 9400 9200 9000>,
			<8800 8600 8400 8200 8000 7800>,
			<7600 7400 7200 7000 6800 6600>,
			<6400 6200 6000 5800 5600 5400>,
			<5200 5000 4800 4600 4400 4200>,
			<4000 3800 3600 3400 3200 3000>,
			<2800 2600 2400 2200 2000 1800>,
			<1600 1400 1200 1000 900 800>,
			<700 600 500 400 300 200>,
			<100 0>;
		qcom,lut-data = <17604 17079 16721 16547 16492 16483>,
			<17664 17170 16743 16539 16490 16480>,
			<17749 17255 16762 16533 16489 16477>,
			<17836 17325 16777 16530 16488 16476>,
			<17902 17372 16787 16528 16487 16475>,
			<17923 17385 16789 16529 16487 16475>,
			<17913 17362 16783 16531 16488 16475>,
			<17901 17334 16776 16535 16491 16477>,
			<17981 17328 16778 16542 16494 16479>,
			<18215 17338 16785 16550 16500 16482>,
			<18305 17392 16795 16554 16503 16485>,
			<18286 17610 16807 16554 16504 16490>,
			<18245 17788 16825 16555 16505 16495>,
			<18001 17649 16874 16567 16510 16497>,
			<17554 17345 16939 16593 16520 16499>,
			<17417 17248 16951 16613 16530 16503>,
			<17400 17245 16940 16628 16543 16513>,
			<17383 17241 16934 16648 16558 16524>,
			<17332 17201 16944 16696 16576 16537>,
			<17263 17137 16956 16743 16596 16553>,
			<17222 17082 16925 16738 16618 16573>,
			<17193 17028 16800 16695 16641 16599>,
			<17182 16985 16711 16645 16645 16605>,
			<17194 16949 16664 16574 16567 16545>,
			<17214 16926 16639 16520 16489 16482>,
			<17234 16930 16651 16513 16484 16477>,
			<17257 16951 16683 16511 16483 16476>,
			<17282 16978 16687 16511 16483 16476>,
			<17311 17012 16642 16516 16487 16479>,
			<17338 17053 16607 16523 16493 16484>,
			<17357 17096 16626 16527 16501 16491>,
			<17373 17143 16666 16532 16511 16501>,
			<17394 17193 16684 16535 16521 16512>,
			<17423 17247 16699 16537 16533 16525>,
			<17455 17307 16716 16540 16538 16530>,
			<17488 17378 16751 16548 16520 16507>,
			<17522 17457 16801 16554 16498 16479>,
			<17556 17544 16848 16552 16492 16474>,
			<17592 17645 16895 16545 16490 16473>,
			<17606 17688 16932 16544 16490 16474>,
			<17532 17689 16964 16558 16500 16484>,
			<17413 17686 16976 16569 16503 16488>,
			<17281 17619 16979 16574 16501 16487>,
			<17224 17465 16951 16589 16510 16490>,
			<17145 17091 16817 16552 16488 16469>,
			<17160 17135 16875 16578 16501 16486>,
			<17185 17188 16921 16604 16515 16500>,
			<17249 17242 16985 16634 16535 16520>,
			<17305 17306 17073 16676 16563 16555>,
			<17343 17379 17181 16726 16587 16560>,
			<17341 17393 17224 16731 16551 16510>,
			<17283 17223 17204 16748 16552 16510>,
			<17362 17093 17243 16840 16595 16529>,
			<17878 17075 17150 16994 16701 16613>,
			<17878 17075 17150 16994 16701 16613>,
			<17878 17075 17150 16994 16701 16613>;
	};

	qcom,pc-temp-y5-lut {
		qcom,lut-col-legend = <(-10) 0 10 25 40 50>;
		qcom,lut-row-legend = <10000 9800 9600 9400 9200 9000>,
			<8800 8600 8400 8200 8000 7800>,
			<7600 7400 7200 7000 6800 6600>,
			<6400 6200 6000 5800 5600 5400>,
			<5200 5000 4800 4600 4400 4200>,
			<4000 3800 3600 3400 3200 3000>,
			<2800 2600 2400 2200 2000 1800>,
			<1600 1400 1200 1000 900 800>,
			<700 600 500 400 300 200>,
			<100 0>;
		qcom,lut-data = <10484 11363 13924 13114 14321 14635>,
			<10655 11251 14139 13782 14207 14854>,
			<10817 11213 14441 14170 14076 14950>,
			<10969 11237 14752 14339 13948 14963>,
			<11105 11310 14992 14351 13840 14936>,
			<11224 11428 15082 14262 13767 14906>,
			<11334 11948 15083 13953 13619 14836>,
			<11422 12524 15059 13548 13444 14711>,
			<11445 12418 14962 13219 13255 14436>,
			<11423 11804 14713 12912 12958 13932>,
			<11658 11660 14394 12893 12914 13573>,
			<13872 12337 13815 13621 13482 13285>,
			<15840 12992 13412 14231 13953 13124>,
			<14639 13491 13516 13874 13831 13459>,
			<11990 14266 13772 13183 13514 14087>,
			<11346 14465 13975 13030 13196 14128>,
			<11747 14650 14139 13095 12785 13588>,
			<12032 14674 14363 13164 12586 13257>,
			<11997 14211 15046 13252 12715 13325>,
			<11907 13554 15927 13429 13026 13484>,
			<11751 13020 16337 14111 13876 13989>,
			<11442 12443 16586 15775 15730 15211>,
			<11268 12008 16712 16452 16464 15720>,
			<11241 11694 16824 16227 15937 15580>,
			<11236 11471 16908 15995 15391 15425>,
			<11267 11399 15643 15998 15348 15475>,
			<11344 11353 12579 16068 15341 15626>,
			<11427 11343 11850 16014 15398 15605>,
			<11505 11369 13661 15773 15841 15297>,
			<11609 11414 15029 15608 16165 15094>,
			<11830 11504 14526 15704 15997 15059>,
			<12216 11686 13563 15940 15727 15012>,
			<12606 11904 13556 16317 15814 15063>,
			<13017 12199 14810 17115 16366 15359>,
			<13453 12516 15621 17465 16762 15614>,
			<13904 12824 15541 17254 17123 15773>,
			<14387 13136 15387 17035 17474 15853>,
			<14994 13432 15215 16992 16873 15779>,
			<15809 13713 14996 16814 14956 15579>,
			<16189 13987 14871 16491 14279 15324>,
			<16070 14265 14828 15472 15108 14941>,
			<15693 14529 14782 15005 15464 14803>,
			<13338 14789 14722 14977 15355 14527>,
			<12154 14765 14397 15196 14987 15809>,
			<11682 13518 12895 16070 14233 15092>,
			<11551 14010 12965 15516 15451 14290>,
			<11630 14558 13008 15512 14942 14336>,
			<11615 14826 13088 15260 14493 14594>,
			<11828 15070 13299 15144 14948 14776>,
			<12353 15196 13446 15007 15128 14905>,
			<12440 15177 13815 15752 16213 15739>,
			<11789 14325 14573 16301 16767 16208>,
			<10929 12641 15894 15828 16703 16415>,
			<9963 11751 15567 15793 16889 17236>,
			<9963 11751 15567 15793 16889 17236>,
			<9963 11751 15567 15793 16889 17236>;
	};

	qcom,pc-temp-y6-lut {
		qcom,lut-col-legend = <(-10) 0 10 25 40 50>;
		qcom,lut-row-legend = <10000 9800 9600 9400 9200 9000>,
			<8800 8600 8400 8200 8000 7800>,
			<7600 7400 7200 7000 6800 6600>,
			<6400 6200 6000 5800 5600 5400>,
			<5200 5000 4800 4600 4400 4200>,
			<4000 3800 3600 3400 3200 3000>,
			<2800 2600 2400 2200 2000 1800>,
			<1600 1400 1200 1000 900 800>,
			<700 600 500 400 300 200>,
			<100 0>;
		qcom,lut-data = <7648 6162 5454 5117 5050 5036>,
			<7553 6143 5453 5116 5049 5035>,
			<7463 6124 5450 5115 5049 5035>,
			<7378 6106 5446 5114 5048 5035>,
			<7299 6090 5441 5113 5048 5035>,
			<7227 6077 5435 5113 5049 5035>,
			<7155 6066 5426 5112 5049 5036>,
			<7096 6056 5418 5112 5050 5036>,
			<7063 6043 5414 5112 5050 5037>,
			<7039 6023 5411 5113 5052 5038>,
			<7029 6020 5411 5115 5053 5038>,
			<7033 6060 5413 5119 5055 5040>,
			<7034 6097 5415 5123 5058 5041>,
			<6942 6058 5424 5128 5061 5044>,
			<6755 5972 5436 5133 5063 5046>,
			<6690 5942 5436 5139 5066 5049>,
			<6678 5941 5427 5144 5069 5051>,
			<6667 5937 5421 5152 5073 5054>,
			<6652 5916 5421 5166 5080 5059>,
			<6636 5884 5421 5179 5089 5065>,
			<6624 5857 5410 5176 5096 5072>,
			<6613 5831 5369 5160 5103 5080>,
			<6609 5818 5341 5142 5104 5081>,
			<6617 5814 5328 5118 5076 5058>,
			<6632 5812 5320 5101 5048 5035>,
			<6651 5817 5313 5099 5046 5034>,
			<6676 5834 5307 5099 5046 5034>,
			<6703 5855 5306 5099 5046 5034>,
			<6734 5880 5311 5100 5048 5035>,
			<6768 5910 5317 5103 5051 5037>,
			<6806 5944 5324 5105 5054 5039>,
			<6850 5984 5332 5108 5057 5042>,
			<6896 6026 5345 5111 5060 5046>,
			<6946 6072 5367 5114 5065 5050>,
			<6999 6122 5390 5117 5067 5052>,
			<7055 6177 5414 5121 5062 5045>,
			<7115 6236 5439 5124 5056 5037>,
			<7177 6298 5465 5124 5053 5036>,
			<7247 6364 5492 5124 5051 5036>,
			<7301 6426 5519 5124 5051 5036>,
			<7341 6485 5547 5129 5057 5040>,
			<7359 6539 5573 5134 5060 5042>,
			<7362 6590 5599 5139 5060 5042>,
			<7384 6605 5608 5147 5063 5046>,
			<7348 6525 5566 5135 5053 5036>,
			<7498 6653 5635 5149 5063 5044>,
			<7587 6733 5680 5162 5069 5051>,
			<7696 6816 5736 5178 5077 5060>,
			<7820 6909 5808 5200 5091 5074>,
			<7970 7019 5888 5224 5101 5076>,
			<8140 7118 5951 5237 5090 5060>,
			<8342 7158 6004 5260 5094 5063>,
			<8937 7241 6101 5321 5116 5074>,
			<10395 7456 6155 5406 5165 5111>,
			<10395 7456 6155 5406 5165 5111>,
			<10395 7456 6155 5406 5165 5111>;
	};

};
